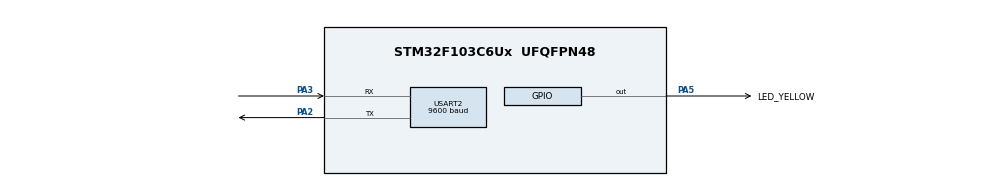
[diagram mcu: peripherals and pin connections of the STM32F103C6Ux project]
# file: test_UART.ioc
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Mcu.Family=STM32F1
Mcu.Name=STM32F103C6Ux
Mcu.Package=UFQFPN48
NVIC.PriorityGroup=NVIC_PRIORITYGROUP_4
NVIC.TIM2_IRQn=true\:0\:0\:false\:false\:true\:true\:true
NVIC.USART2_IRQn=true\:0\:0\:false\:false\:true\:true\:true
PA2.Mode=Asynchronous
PA2.Signal=USART2_TX
PA3.Mode=Asynchronous
PA3.Signal=USART2_RX
PA5.GPIO_Label=LED_YELLOW
PA5.Signal=GPIO_Output
ProjectManager.HeapSize=0x200
ProjectManager.StackSize=0x400
ProjectManager.TargetToolchain=STM32CubeIDE
RCC.APB1Freq_Value=8000000
RCC.APB2Freq_Value=8000000
TIM2.Period=9
TIM2.Prescaler=7999
USART2.BaudRate=9600
USART2.VirtualMode=VM_ASYNC
VP_SYS_VS_ND.Mode=No_Debug
VP_TIM2_VS_ClockSourceINT.Mode=Internal
board=custom

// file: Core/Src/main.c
/* USER CODE BEGIN Header */
/**
  ******************************************************************************
  * @file           : main.c
  * @brief          : Main program body
  ******************************************************************************
  * @attention
  *
  * <h2><center>&copy; Copyright (c) 2022 STMicroelectronics.
  * All rights reserved.</center></h2>
  *
  * This software component is licensed by ST under BSD 3-Clause license,
  * the "License"; You may not use this file except in compliance with the
  * License. You may obtain a copy of the License at:
  *                        opensource.org/licenses/BSD-3-Clause
  *
  ******************************************************************************
  */
/* USER CODE END Header */
#include "main.h"

/* USER CODE BEGIN Includes */
#include "software_timer.h"
#include "stdio.h"
#include "string.h"
/* USER CODE END Includes */

TIM_HandleTypeDef htim2;

UART_HandleTypeDef huart2;

void SystemClock_Config(void);
static void MX_TIM2_Init(void);
static void MX_GPIO_Init(void);
static void MX_USART2_UART_Init(void);

/* USER CODE BEGIN 0 */
uint8_t system_space[] = " ";
uint8_t system_counter[] = "\r\nEnter counter and press space:";
uint8_t system_enter[] = "\r\n";
uint8_t system_tutorial1[] = " -Enter !RST# to Run program.\r\n";
uint8_t system_tutorial2[] = " -Enter !OK# to Confirm and End program.\r\n";
uint8_t system_success[] = "\r\nSuccess!\r\n";
uint8_t system_error[] = "\r\nError! Please enter again!\r\n";

uint8_t counter = 0;
uint8_t input = 0;
uint8_t buffer[MAX_BUFFER_SIZE];
uint8_t index_buffer = 0;
uint8_t buffer_flag = 0;
uint8_t success_flag = 0;
char str[30];
int status_command;
int status_UART;

void command_parser_fsm(){
	switch(status_command){
	case	INIT:
		if(input == '!'){
			counter = 0;
			status_command = RST_1;
		} else {
			 HAL_UART_Transmit(&huart2, system_error, sizeof(system_error), 1000);
		}
		break;
	case	RST_1:
		if(input == 'R'){
			status_command = RST_2;
		} else {
			status_command = INIT;
			HAL_UART_Transmit(&huart2, system_error, sizeof(system_error), 1000);
		}
		break;
	case	RST_2:
		if(input == 'S'){
			status_command = RST_3;
		} else {
			status_command = INIT;
			HAL_UART_Transmit(&huart2, system_error, sizeof(system_error), 1000);
		}
		break;
	case	RST_3:
		if(input == 'T'){
			status_command = RST_4;
		} else {
			status_command = INIT;
			HAL_UART_Transmit(&huart2, system_error, sizeof(system_error), 1000);
		}
		break;
	case	RST_4:
		if(input == '#'){
			HAL_UART_Transmit(&huart2, system_counter, sizeof(system_counter), 1000);
			HAL_UART_Transmit(&huart2, system_enter, sizeof(system_enter), 1000);
			status_command = ENTER_COUNTER;
		} else {
			status_command = INIT;
			HAL_UART_Transmit(&huart2, system_error, sizeof(system_error), 1000);
		}
		break;
	case	START:
		if(input == '!'){
			status_command = OK_1;
		} else {
			status_command = START;
			HAL_UART_Transmit(&huart2, system_error, sizeof(system_error), 1000);
		}
		break;
	case	OK_1:
		if(input == 'O'){
			status_command = OK_2;
		} else {
			status_command = START;
			HAL_UART_Transmit(&huart2, system_error, sizeof(system_error), 1000);
		}
		break;
	case	OK_2:
		if(input == 'K'){
			status_command = OK_3;
		} else {
			status_command = START;
			HAL_UART_Transmit(&huart2, system_error, sizeof(system_error), 1000);
		}
		break;
	case	OK_3:
		if(input == '#'){
			status_UART = OK;
			status_command = INIT;
		} else {
			status_command = START;
			HAL_UART_Transmit(&huart2, system_error, sizeof(system_error), 1000);
		}
		break;
	case ENTER_COUNTER:
		if(input == ' '){
			status_UART = RST;
			HAL_UART_Transmit(&huart2, system_enter, sizeof(system_enter), 1000);
		} else {
			counter = counter*10 + (input-48);
		}
		break;
	default:
		break;
	}
}

void uart_communiation_fsm(){
	switch(status_UART){
	case INIT:
		if(success_flag == 1){
			HAL_UART_Transmit(&huart2, (void*)str, sprintf(str, "count: %d s\r\n",counter), 1000);
		HAL_UART_Transmit(&huart2, system_success, sizeof(system_success), 1000);
			success_flag = 0;
		}
		break;
	case RST:
		if (timer1_flag == 1){
			HAL_UART_Transmit(&huart2, (void*)str, sprintf(str, "count: %d s\r\n",counter), 1000);
			counter--;
			if(counter == 0){
				status_UART = OK;
			}
			status_command = START;
			setTimer1(1000);
		}
		break;
	case OK:
		HAL_Delay(3000);
		success_flag = 1;
		status_UART = INIT;
		setTimer1(3000);
		break;
	default:
		break;
	}
}

void HAL_UART_RxCpltCallback(UART_HandleTypeDef *huart){
	if(huart->Instance == USART2){
		buffer[index_buffer++] = input;
		if(index_buffer == 30) index_buffer = 0;
		buffer_flag = 1;
		HAL_UART_Receive_IT(&huart2, &input, 1);
		HAL_UART_Transmit(&huart2, &input, 1, 1000);
	}
}
/* USER CODE END 0 */

int main(void)
{

  /* MCU Configuration--------------------------------------------------------*/

  /* Reset of all peripherals, Initializes the Flash interface and the Systick. */
  HAL_Init();

  /* Configure the system clock */
  SystemClock_Config();

  /* Initialize all configured peripherals */
  MX_TIM2_Init();
  MX_GPIO_Init();
  MX_USART2_UART_Init();
  /* USER CODE BEGIN 2 */
  HAL_UART_Receive_IT(&huart2, &input, 1);
   HAL_TIM_Base_Start_IT(&htim2);
  /* USER CODE END 2 */

  /* Infinite loop */
  /* USER CODE BEGIN WHILE */
   HAL_UART_Transmit(&huart2, system_space, sizeof(system_space), 1000);
   HAL_UART_Transmit(&huart2, system_tutorial1, sizeof(system_tutorial1), 1000);
   HAL_UART_Transmit(&huart2, system_tutorial2, sizeof(system_tutorial2), 1000);
   timer1_flag = 1;
  while (1)
  {
	  if(buffer_flag == 1){
	  		  command_parser_fsm();
	  		  buffer_flag = 0;
	  	  }
	  	  uart_communiation_fsm();
    /* USER CODE END WHILE */

  }
}

void SystemClock_Config(void)
{
  RCC_OscInitTypeDef RCC_OscInitStruct = {0};
  RCC_ClkInitTypeDef RCC_ClkInitStruct = {0};

  /** Initializes the RCC Oscillators according to the specified parameters
  * in the RCC_OscInitTypeDef structure.
  */
  RCC_OscInitStruct.OscillatorType = RCC_OSCILLATORTYPE_HSI;
  RCC_OscInitStruct.HSIState = RCC_HSI_ON;
  RCC_OscInitStruct.HSICalibrationValue = RCC_HSICALIBRATION_DEFAULT;
  RCC_OscInitStruct.PLL.PLLState = RCC_PLL_NONE;
  if (HAL_RCC_OscConfig(&RCC_OscInitStruct) != HAL_OK)
  {
    Error_Handler();
  }
  /** Initializes the CPU, AHB and APB buses clocks
  */
  RCC_ClkInitStruct.ClockType = RCC_CLOCKTYPE_HCLK|RCC_CLOCKTYPE_SYSCLK
                              |RCC_CLOCKTYPE_PCLK1|RCC_CLOCKTYPE_PCLK2;
  RCC_ClkInitStruct.SYSCLKSource = RCC_SYSCLKSOURCE_HSI;
  RCC_ClkInitStruct.AHBCLKDivider = RCC_SYSCLK_DIV1;
  RCC_ClkInitStruct.APB1CLKDivider = RCC_HCLK_DIV1;
  RCC_ClkInitStruct.APB2CLKDivider = RCC_HCLK_DIV1;

  if (HAL_RCC_ClockConfig(&RCC_ClkInitStruct, FLASH_LATENCY_0) != HAL_OK)
  {
    Error_Handler();
  }
}

static void MX_TIM2_Init(void)
{

  TIM_ClockConfigTypeDef sClockSourceConfig = {0};
  TIM_MasterConfigTypeDef sMasterConfig = {0};

  htim2.Instance = TIM2;
  htim2.Init.Prescaler = 7999;
  htim2.Init.CounterMode = TIM_COUNTERMODE_UP;
  htim2.Init.Period = 9;
  htim2.Init.ClockDivision = TIM_CLOCKDIVISION_DIV1;
  htim2.Init.AutoReloadPreload = TIM_AUTORELOAD_PRELOAD_DISABLE;
  if (HAL_TIM_Base_Init(&htim2) != HAL_OK)
  {
    Error_Handler();
  }
  sClockSourceConfig.ClockSource = TIM_CLOCKSOURCE_INTERNAL;
  if (HAL_TIM_ConfigClockSource(&htim2, &sClockSourceConfig) != HAL_OK)
  {
    Error_Handler();
  }
  sMasterConfig.MasterOutputTrigger = TIM_TRGO_RESET;
  sMasterConfig.MasterSlaveMode = TIM_MASTERSLAVEMODE_DISABLE;
  if (HAL_TIMEx_MasterConfigSynchronization(&htim2, &sMasterConfig) != HAL_OK)
  {
    Error_Handler();
  }

}

static void MX_USART2_UART_Init(void)
{

  huart2.Instance = USART2;
  huart2.Init.BaudRate = 9600;
  huart2.Init.WordLength = UART_WORDLENGTH_8B;
  huart2.Init.StopBits = UART_STOPBITS_1;
  huart2.Init.Parity = UART_PARITY_NONE;
  huart2.Init.Mode = UART_MODE_TX_RX;
  huart2.Init.HwFlowCtl = UART_HWCONTROL_NONE;
  huart2.Init.OverSampling = UART_OVERSAMPLING_16;
  if (HAL_UART_Init(&huart2) != HAL_OK)
  {
    Error_Handler();
  }

}

static void MX_GPIO_Init(void)
{
  GPIO_InitTypeDef GPIO_InitStruct = {0};

  /* GPIO Ports Clock Enable */
  __HAL_RCC_GPIOA_CLK_ENABLE();

  /*Configure GPIO pin Output Level */
  HAL_GPIO_WritePin(LED_YELLOW_GPIO_Port, LED_YELLOW_Pin, GPIO_PIN_RESET);

  /*Configure GPIO pin : LED_YELLOW_Pin */
  GPIO_InitStruct.Pin = LED_YELLOW_Pin;
  GPIO_InitStruct.Mode = GPIO_MODE_OUTPUT_PP;
  GPIO_InitStruct.Pull = GPIO_NOPULL;
  GPIO_InitStruct.Speed = GPIO_SPEED_FREQ_LOW;
  HAL_GPIO_Init(LED_YELLOW_GPIO_Port, &GPIO_InitStruct);

}

/* USER CODE BEGIN 4 */
void HAL_TIM_PeriodElapsedCallback(TIM_HandleTypeDef *htim) {
	timeRun();
}
/* USER CODE END 4 */

void Error_Handler(void)
{
  __disable_irq();
  while (1)
  {
  }
}

/************************ (C) COPYRIGHT STMicroelectronics *****END OF FILE****/
